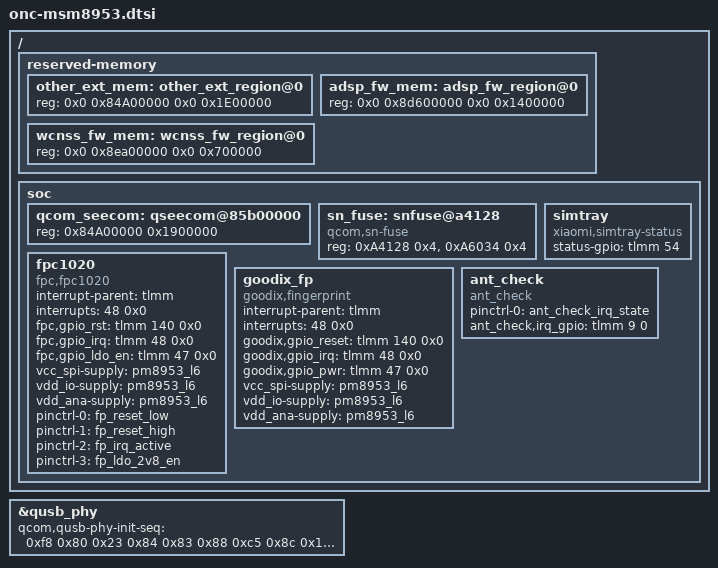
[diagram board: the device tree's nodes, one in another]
/*
 * Copyright (c) 2015-2019, The Linux Foundation. All rights reserved.
 * Copyright (C) 2020-2024 XiaoMi, Inc.
 *
 * This program is free software; you can redistribute it and/or modify
 * it under the terms of the GNU General Public License version 2 and
 * only version 2 as published by the Free Software Foundation.
 */

/ {
	reserved-memory {
		other_ext_mem: other_ext_region@0 {
			reg = <0x0 0x84A00000 0x0 0x1E00000>;
		};
		adsp_fw_mem: adsp_fw_region@0 {
			reg = <0x0 0x8d600000 0x0 0x1400000>;
		};
		wcnss_fw_mem: wcnss_fw_region@0 {
			reg = <0x0 0x8ea00000 0x0 0x700000>;
		};
	};

	soc {
		qcom_seecom: qseecom@85b00000 {
			reg = <0x84A00000 0x1900000>;
		};

		sn_fuse: snfuse@a4128 {
			compatible = "qcom,sn-fuse";
			reg = <0xA4128 0x4>,
			      <0xA6034 0x4>;
			reg-names = "sn-base","fuse-state";
		};

		fpc1020 {
			status = "ok";
			compatible = "fpc,fpc1020";
			interrupt-parent = <&tlmm>;
			interrupts = <48 0x0>;
			fpc,gpio_rst = <&tlmm 140 0x0>;
			fpc,gpio_irq = <&tlmm 48 0x0>;
			fpc,gpio_ldo_en = <&tlmm 47 0x0>;
			vcc_spi-supply = <&pm8953_l6>;
			vdd_io-supply = <&pm8953_l6>;
			vdd_ana-supply = <&pm8953_l6>;
			pinctrl-names = "fpc1020_reset_reset",
				"fpc1020_reset_active",
				"fpc1020_irq_active",
				"fpc1020_ldo_2v8_en";
			pinctrl-0 = <&fp_reset_low>;
			pinctrl-1 = <&fp_reset_high>;
			pinctrl-2 = <&fp_irq_active>;
			pinctrl-3 = <&fp_ldo_2v8_en>;
		};

		goodix_fp {
			status = "ok";
			compatible = "goodix,fingerprint";
			interrupt-parent = <&tlmm>;
			interrupts = <48 0x0>;
			goodix,gpio_reset = <&tlmm 140 0x0>;
			goodix,gpio_irq = <&tlmm 48 0x0>;
			goodix,gpio_pwr = <&tlmm 47 0x0>;
			vcc_spi-supply = <&pm8953_l6>;
			vdd_io-supply = <&pm8953_l6>;
			vdd_ana-supply = <&pm8953_l6>;
		};

		simtray {
			compatible = "xiaomi,simtray-status";
			status-gpio = <&tlmm 54 0x00>;
		};

		ant_check {
			compatible = "ant_check";
			pinctrl-names = "ant_check_irq_state";
			pinctrl-0 = <&ant_check_irq_state>;
			ant_check,irq_gpio = <&tlmm 9 0>;
		};
	};
};

&qusb_phy {
	qcom,qusb-phy-init-seq = <0xf8 0x80
				0x23 0x84
				0x83 0x88
				0xc5 0x8c
				0x14 0x9c
				0x30 0x08
				0x79 0x0c
				0x21 0x10
				0x00 0x90
				0x9f 0x1c
				0x00 0x18>;
};
